VERSION ""

NS_ :

BS_:

BU_: Lamp_ECU BCM_ECU TMEP_ECU
VAL_TABLE_ New_Value_Table_5 1 "ECU on" 0 "ECU Off" ;
VAL_TABLE_ tempModificationDirection 2 "decrease temp" 1 "increase temp" 0 "doNothing" ;
VAL_TABLE_ tempStatusIndicator_VT 2 "Hight Temperature (temp >= 100)" 1 "Low Temperature  (temp <= 40)" 0 "Normal Temperature (40>temp<100)" ;

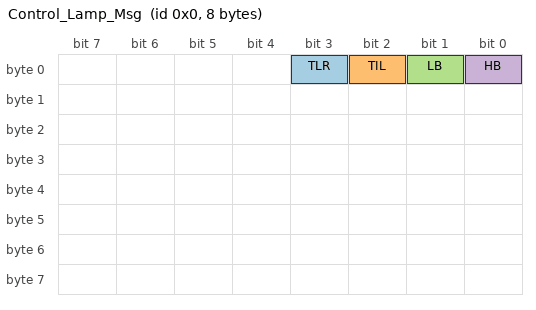
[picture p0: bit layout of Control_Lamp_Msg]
BO_ 0 Control_Lamp_Msg: 8 BCM_ECU
 SG_ TLR : 3|1@1+ (1,0) [0|1] ""  Lamp_ECU
 SG_ TIL : 2|1@1+ (1,0) [0|1] ""  Lamp_ECU
 SG_ LB : 1|1@1+ (1,0) [0|1] ""  Lamp_ECU
 SG_ HB : 0|1@1+ (1,0) [0|1] ""  Lamp_ECU

BO_ 768 ControlNetworkNode: 1 BCM_ECU
 SG_ Temp_ECUControl : 0|1@1+ (1,0) [0|1] "" Vector__XXX

BO_ 512 ControlTemp: 2 BCM_ECU
 SG_ tempModificationDirection : 8|2@1- (1,0) [-1|1] "" Vector__XXX
 SG_ modifiedTempDegree : 0|8@1+ (1,0) [0|255] "" Vector__XXX

BO_ 256 temperatureStatus: 2 TMEP_ECU
 SG_ tempStatusIndicator : 8|2@1+ (1,0) [-1|1] "" Vector__XXX
 SG_ tempDegree : 0|8@1+ (1,0) [0|255] "celsius" Vector__XXX

BA_DEF_ BO_  "CANFD_BRS" ENUM  "0","1";
BA_DEF_  "DBName" STRING ;
BA_DEF_  "BusType" STRING ;
BA_DEF_ BO_  "VFrameFormat" ENUM  "StandardCAN","ExtendedCAN","reserved","reserved","reserved","reserved","reserved","reserved","reserved","reserved","reserved","reserved","reserved","reserved","StandardCAN_FD","ExtendedCAN_FD";
BA_DEF_DEF_  "CANFD_BRS" "1";
BA_DEF_DEF_  "DBName" "";
BA_DEF_DEF_  "BusType" "";
BA_DEF_DEF_  "VFrameFormat" "StandardCAN";
BA_ "BusType" "CAN FD";
BA_ "DBName" "CAN_FD";
VAL_ 512 tempModificationDirection 2 "decrease temp" 1 "increase temp" 0 "doNothing" ;
VAL_ 256 tempStatusIndicator 2 "Hight Temp (temp > 100)" 1 "Low Temp (temp < 40)" 0 "Normal Temp(40>=temp<=100)" ;
